VERSION "RT_STACK_V2"

NS_ :

BS_:

BU_: RT_STACK RECEIVER

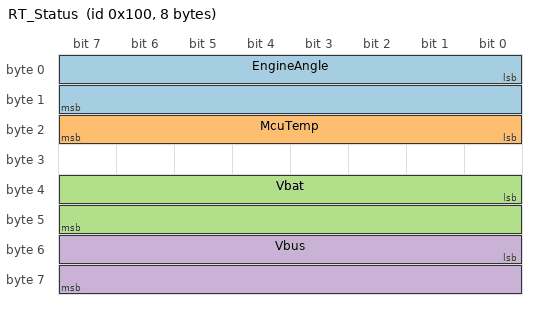
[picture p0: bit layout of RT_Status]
BO_ 256 RT_Status: 8 RT_STACK
 SG_ EngineAngle : 0|16@1+ (0.1,0) [0|720] "deg" RECEIVER
 SG_ McuTemp : 16|8@1- (1,0) [-40|150] "degC" RECEIVER
 SG_ Vbat : 32|16@1+ (1,0) [0|4095] "count" RECEIVER
 SG_ Vbus : 48|16@1+ (1,0) [0|4095] "count" RECEIVER

CM_ BO_ 256 "Telemetria base RT_STACK: angolo motore, temperatura MCU, tensioni raw";
CM_ SG_ 256 EngineAngle "Angolo motore 0..720 gradi, risoluzione 0.1 deg";
CM_ SG_ 256 McuTemp "Temperatura die MCU dal sensore interno";
CM_ SG_ 256 Vbat "Lettura ADC raw canale VBAT (12 bit)";
CM_ SG_ 256 Vbus "Lettura ADC raw canale VBUS (12 bit)";

BA_DEF_ BO_ "GenMsgCycleTime" INT 0 10000;
BA_DEF_DEF_ "GenMsgCycleTime" 10;
